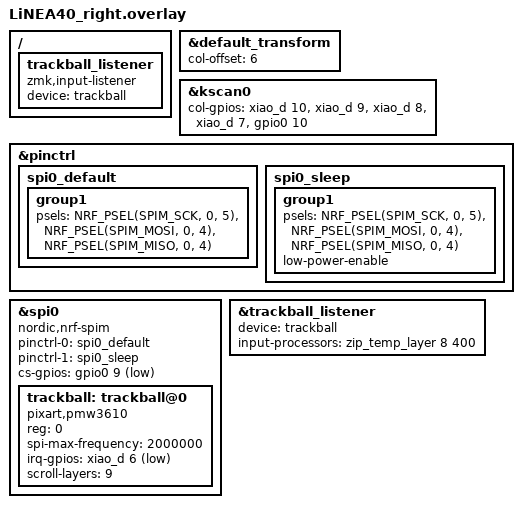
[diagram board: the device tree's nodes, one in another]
#include "LiNEA40.dtsi"
&default_transform {
    col-offset = <6>;
};

&kscan0 {
    col-gpios
        = <&xiao_d 10 GPIO_ACTIVE_HIGH> //col0-D10
        , <&xiao_d 9 GPIO_ACTIVE_HIGH>  //col1-D9
        , <&xiao_d 8 GPIO_ACTIVE_HIGH>  //col2-D8
        , <&xiao_d 7 GPIO_ACTIVE_HIGH>  //col3-D7
        , <&gpio0 10 GPIO_ACTIVE_HIGH>  //col4-NFC2
        ;
};

/ {
    trackball_listener {
        compatible = "zmk,input-listener";
        device = <&trackball>;

    };
};


&pinctrl {
    spi0_default: spi0_default {
        group1 {
            psels = <NRF_PSEL(SPIM_SCK, 0, 5)>   // SCLK-D5
                  , <NRF_PSEL(SPIM_MOSI, 0, 4)>  // SDIO-D4
                  , <NRF_PSEL(SPIM_MISO, 0, 4)>  // SDIO-D4
                  ;
        };
    };

    spi0_sleep: spi0_sleep {
        group1 {
            psels = <NRF_PSEL(SPIM_SCK, 0, 5)>   // SCLK-D5
                  , <NRF_PSEL(SPIM_MOSI, 0, 4)>  // SDIO-D4
                  , <NRF_PSEL(SPIM_MISO, 0, 4)>  // SDIO-D4
                  ;
            low-power-enable;
        };
    };
};

&spi0 {
    status = "okay";
    compatible = "nordic,nrf-spim";
    pinctrl-0 = <&spi0_default>;
    pinctrl-1 = <&spi0_sleep>;
    pinctrl-names = "default", "sleep";
    cs-gpios = <&gpio0 9 GPIO_ACTIVE_LOW>; //NCS-NFC1

    trackball: trackball@0 {
        status = "okay";
        compatible = "pixart,pmw3610";
        reg = <0>;
        spi-max-frequency = <2000000>;
        irq-gpios = <&xiao_d 6 (GPIO_ACTIVE_LOW | GPIO_PULL_UP)>; //MOT-D6
        //automouse-layer = <1>;
        /* v2.0: snipe-layers = <2> を削除。旧レイヤー構成の残骸で、
         * Win_Base(2)で常時スナイプ（カーソル半速）になっていた。
         * 注意: この修正でWindowsでのカーソルが従来より速くなる */
        /* v2.1: スクロール層は9（SymNum）。このドライバは「最上位レイヤー」で
         * スクロール判定するため、AML(8)はSymNum(9)より下の番号に配置してある */
        scroll-layers = <9>;
    };
};

&trackball_listener {
    status = "okay";
    device = <&trackball>;
    /* v2.0: AML（自動マウスレイヤー）。玉を動かすとレイヤー11(Mouse)が有効になり、
     * 最後の玉の動きまたはクリックから400msで解除（クリック延命はkeymap側の
     * mkp_input_listener設定と、excluded-positions等はkeymap側のzip_temp_layer
     * 設定を参照。Aerogu34 v1.6と同方式）
     * v2.1: Mouseレイヤーは8（スクロール判定の都合でSymNumより下に配置） */
    input-processors = <&zip_temp_layer 8 400>;
};
